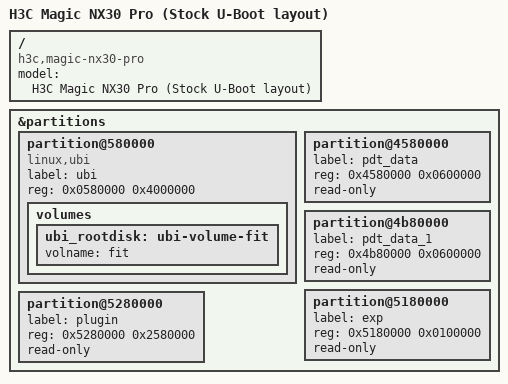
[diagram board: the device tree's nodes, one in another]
// SPDX-License-Identifier: GPL-2.0-or-later OR MIT

/dts-v1/;
#include "mt7981b-h3c-magic-nx30-pro.dtsi"

/ {
	model = "H3C Magic NX30 Pro (Stock U-Boot layout)";
	compatible = "h3c,magic-nx30-pro", "mediatek,mt7981";
};

&partitions {
    partition@580000 {
        label = "ubi";
        reg = <0x0580000 0x4000000>;
		compatible = "linux,ubi";

		volumes {
			ubi_rootdisk: ubi-volume-fit {
				volname = "fit";
			};
		};
    };

    /* yaffs partition */
    partition@4580000 {
        label = "pdt_data";
        reg = <0x4580000 0x0600000>;
        read-only;
    };

    /* yaffs partition */
    partition@4b80000 {
        label = "pdt_data_1";
        reg = <0x4b80000 0x0600000>;
        read-only;
    };

    partition@5180000 {
        label = "exp";
        reg = <0x5180000 0x0100000>;
        read-only;
    };

    partition@5280000 {
        label = "plugin";
        reg = <0x5280000 0x2580000>;
        read-only;
    };
};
